# RX64M_PPG_Pilot register map
File version: 1.0
RX64M_PPG_Pilot peripheral registers generated from iodefine.h (pilot).
Registers are 8-bit, read-write, reset 0x0 unless marked. A register's access mark holds for its fields unless they carry their own. Offsets are from the block's base; lines under a group give offsets from that group; [hi:lo] are bit positions; {n}, {i} and the like mark numbered series; 'fields as' and 'values as' point back to an identical list; <NAME> marks a mode.

## Memory map
0x000881E6 PPG0 size 0xA
0x000881F0 PPG1 size 0x10

## PPG0
Base 0x000881E6
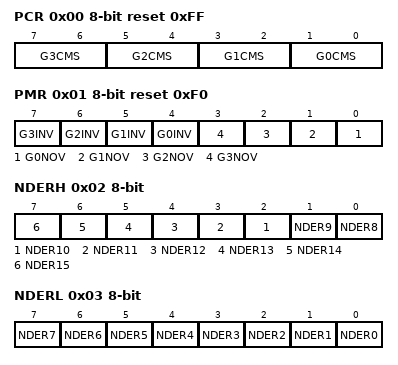
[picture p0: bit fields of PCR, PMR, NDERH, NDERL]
0x00 PCR reset 0xFF
  [2n+1:2n] G{n}CMS (n=0..3)
0x01 PMR reset 0xF0
  [n+4] G{n}INV (n=0..3), [n] G{n}NOV (n=0..3)
0x02 NDERH
  [n-8] NDER{n} (n=8..15)
0x03 NDERL
  [n] NDER{n} (n=0..7)
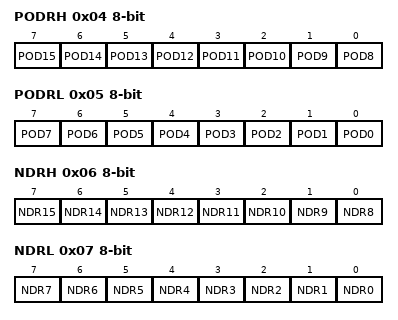
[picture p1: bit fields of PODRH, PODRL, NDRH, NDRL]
0x04 PODRH
  [n-8] POD{n} (n=8..15)
0x05 PODRL
  [n] POD{n} (n=0..7)
0x06 NDRH
  [n-8] NDR{n} (n=8..15)
0x07 NDRL
  [n] NDR{n} (n=0..7)
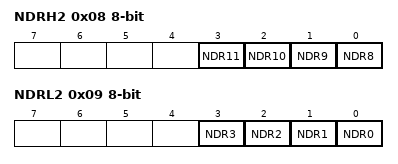
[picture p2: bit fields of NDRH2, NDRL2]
0x08 NDRH2
  [n-8] NDR{n} (n=8..11)
0x09 NDRL2
  [n] NDR{n} (n=0..3)

## PPG1
Base 0x000881F0
0x00 PTRSLR reset 0x1
  [0] PTRSL
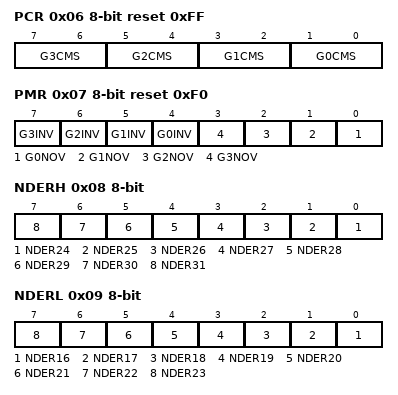
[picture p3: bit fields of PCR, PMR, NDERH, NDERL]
0x06 PCR reset 0xFF
  [2n+1:2n] G{n}CMS (n=0..3)
0x07 PMR reset 0xF0
  [n+4] G{n}INV (n=0..3), [n] G{n}NOV (n=0..3)
0x08 NDERH
  [n-24] NDER{n} (n=24..31)
0x09 NDERL
  [n-16] NDER{n} (n=16..23)
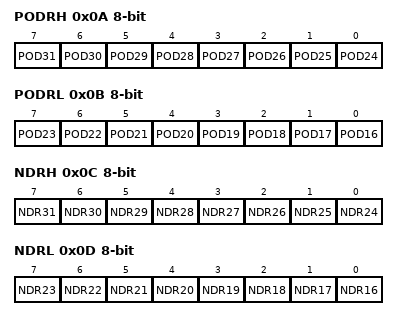
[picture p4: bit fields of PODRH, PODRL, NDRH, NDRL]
0x0A PODRH
  [n-24] POD{n} (n=24..31)
0x0B PODRL
  [n-16] POD{n} (n=16..23)
0x0C NDRH
  [n-24] NDR{n} (n=24..31)
0x0D NDRL
  [n-16] NDR{n} (n=16..23)
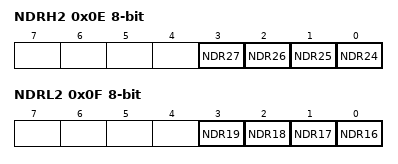
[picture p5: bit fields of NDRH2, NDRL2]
0x0E NDRH2
  [n-24] NDR{n} (n=24..27)
0x0F NDRL2
  [n-16] NDR{n} (n=16..19)
